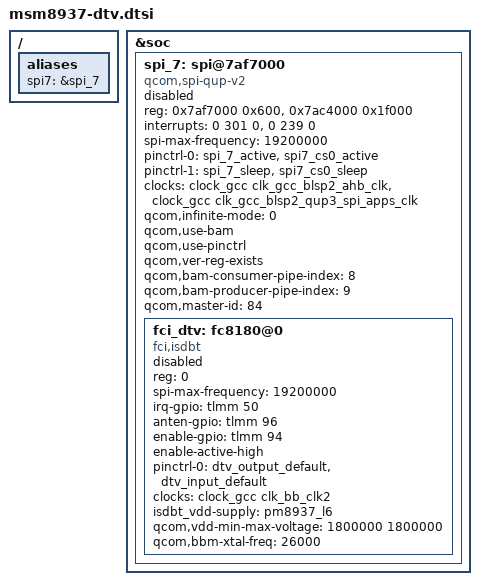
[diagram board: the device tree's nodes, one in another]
/ {
	aliases {
		spi7 = &spi_7;
    };
};

&soc {
	spi_7: spi@7af7000 { /* BLSP2 QUP2 */
		compatible = "qcom,spi-qup-v2";
		#address-cells = <1>;
		#size-cells = <0>;
		reg-names = "spi_physical", "spi_bam_physical";
		reg = <0x7af7000 0x600>,
		       <0x7ac4000 0x1f000>;
		interrupt-names = "spi_irq", "spi_bam_irq";
		/* IRQ 239 for BLSP2 */
		interrupts = <0 301 0>, <0 239 0>;
		spi-max-frequency = <19200000>;
		pinctrl-names = "spi_default", "spi_sleep";
		pinctrl-0 = <&spi_7_active &spi7_cs0_active>;
		pinctrl-1 = <&spi_7_sleep &spi7_cs0_sleep>;
		clocks = <&clock_gcc clk_gcc_blsp2_ahb_clk>,
			 <&clock_gcc clk_gcc_blsp2_qup3_spi_apps_clk>;
		clock-names = "iface_clk", "core_clk";
		qcom,infinite-mode = <0>;
		qcom,use-bam;
		qcom,use-pinctrl;
		qcom,ver-reg-exists;
		/* need to check pipe index setting*/
		qcom,bam-consumer-pipe-index = <8>;
		qcom,bam-producer-pipe-index = <9>;
		/* master-id for BLSP2 is MSM_BUS_MASTER_BLSP_2 or 84 */
		qcom,master-id = <84>;
		status = "/chosen", "mmi,dtv", "true";

		fci_dtv: fc8180@0 {
			status = "/chosen", "mmi,dtv", "true";
			compatible = "fci,isdbt";
			reg = <0>;
			spi-max-frequency = <19200000>;
			irq-gpio = <&tlmm 50 0>;
			anten-gpio = <&tlmm 96 0>;
			enable-gpio = <&tlmm 94 0>;
			enable-active-high;
			pinctrl-names = "default";
			pinctrl-0 = <&dtv_output_default &dtv_input_default>;
			clocks = <&clock_gcc clk_bb_clk2>;
			clock-names = "dtv_refclk";
			isdbt_vdd-supply = <&pm8937_l6>;
			qcom,vdd-min-max-voltage = <1800000 1800000>;
			qcom,bbm-xtal-freq = <26000>;
		};
	};
};
